# STM32L162xD register map
File version: 1.0
Registers are 32-bit, read-write, reset 0x0 unless marked. A register's access mark holds for its fields unless they carry their own. Offsets are from the block's base; [hi:lo] are bit positions; {n}, {i} and the like mark numbered series; 'fields as' and 'values as' point back to an identical list.

## RCC — Reset and Clock Control
Base 0x40023800
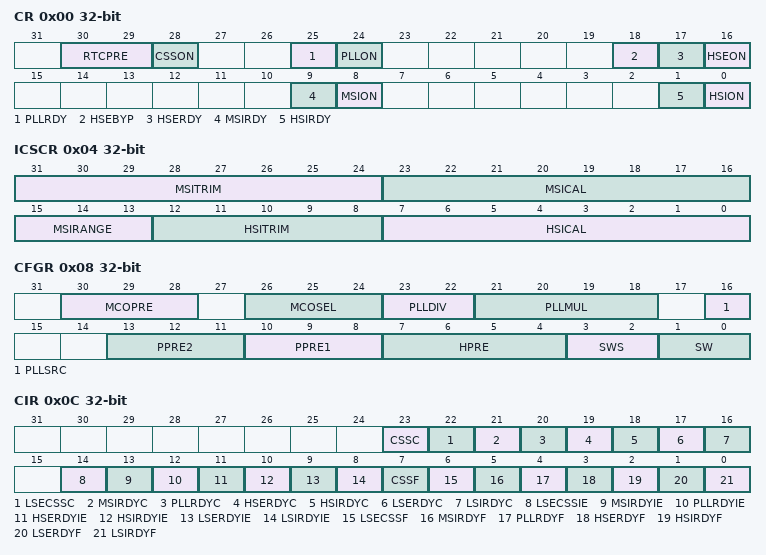
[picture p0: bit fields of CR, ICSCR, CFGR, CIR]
0x00 CR — RCC clock control register
  [30:29] RTCPRE — RTC/LCD Prescaler
    0=DIV_2 (HSE is divided by 2 for RTC clock); 1=DIV_4 (HSE is divided by 4 for RTC clock); 2=DIV_8 (HSE is divided by 8 for RTC clock); 3=DIV_16 (HSE is divided by 16 for RTC clock)
  [28] CSSON — Clock Security System enable
  [25] PLLRDY — PLL clock ready flag
  [24] PLLON — PLL enable
  [18] HSEBYP — External High Speed clock Bypass
  [17] HSERDY — External High Speed clock ready flag
  [16] HSEON — External High Speed clock enable
  [9] MSIRDY — Internal Multi Speed clock ready flag
  [8] MSION — Internal Multi Speed clock enable
  [1] HSIRDY — Internal High Speed clock ready flag
  [0] HSION — Internal High Speed clock enable
0x04 ICSCR — RCC Internal clock sources calibration register
  [31:24] MSITRIM — Internal Multi Speed clock trimming
  [23:16] MSICAL — Internal Multi Speed clock Calibration
  [15:13] MSIRANGE — Internal Multi Speed clock Range
    0=MSI = 65.536 KHz; 1=MSI = 131.072 KHz; 2=MSI = 262.144 KHz; 3=MSI = 524.288 KHz; 4=MSI = 1.048 MHz; 5=MSI = 2.097 MHz; 6=MSI = 4.194 MHz
  [12:8] HSITRIM — Internal High Speed clock trimming
  [7:0] HSICAL — Internal High Speed clock Calibration
0x08 CFGR — RCC Clock configuration register
  [30:28] MCOPRE — MCOPRE[2:0] bits (Microcontroller Clock Output Prescaler)
  [26:24] MCOSEL — MCO[2:0] bits (Microcontroller Clock Output)
  [23:22] PLLDIV — PLLDIV[1:0] bits (PLL Output Division)
    1=DIV_2 (PLL clock output = PLLVCO / 2); 2=DIV_3 (PLL clock output = PLLVCO / 3); 3=DIV_4 (PLL clock output = PLLVCO / 4)
  [21:18] PLLMUL — PLLMUL[3:0] bits (PLL multiplication factor)
    0=MUL_3 (PLL input clock * 3); 1=MUL_4 (PLL input clock * 4); 2=MUL_6 (PLL input clock * 6); 3=MUL_8 (PLL input clock * 8); 4=MUL_12 (PLL input clock * 12); 5=MUL_16 (PLL input clock * 16); 6=MUL_24 (PLL input clock * 24); 7=MUL_32 (PLL input clock * 32); 8=MUL_48 (PLL input clock * 48)
  [16] PLLSRC — PLL entry clock source
    0=HSI (HSI clock selected as PLL entry clock source); 1=HSE (HSE clock selected as PLL entry clock source)
  [13:11] PPRE2 — PRE2[2:0] bits (APB2 prescaler)
    0=DIV_1 (HCLK not divided); 4=DIV_2 (HCLK divided by 2); 5=DIV_4 (HCLK divided by 4); 6=DIV_8 (HCLK divided by 8); 7=DIV_16 (HCLK divided by 16)
  [10:8] PPRE1 — PRE1[2:0] bits (APB1 prescaler)
    values as PPRE2
  [7:4] HPRE — HPRE[3:0] bits (AHB prescaler)
    0=DIV_1 (SYSCLK not divided); 8=DIV_2 (SYSCLK divided by 2); 9=DIV_4 (SYSCLK divided by 4); 10=DIV_8 (SYSCLK divided by 8); 11=DIV_16 (SYSCLK divided by 16); 12=DIV_64 (SYSCLK divided by 64); 13=DIV_128 (SYSCLK divided by 128); 14=DIV_256 (SYSCLK divided by 256); 15=DIV_512 (SYSCLK divided by 512)
  [3:2] SWS — SWS[1:0] bits (System Clock Switch Status)
    0=MSI (MSI used as system clock); 1=HSI (HSI used as system clock); 2=HSE (HSE used as system clock); 3=PLL (PLL used as system clock)
  [1:0] SW — SW[1:0] bits (System clock Switch)
    0=MSI (MSI selection as system clock); 1=HSI (HSI selection as system clock); 2=HSE (HSE selection as system clock); 3=PLL (PLL selection as system clock)
0x0C CIR — RCC Clock interrupt register
  [23] CSSC — Clock Security System Interrupt Clear
  [22] LSECSSC — LSE CSS Interrupt Clear
  [21] MSIRDYC — MSI Ready Interrupt Clear
  [20] PLLRDYC — PLL Ready Interrupt Clear
  [19] HSERDYC — HSE Ready Interrupt Clear
  [18] HSIRDYC — HSI Ready Interrupt Clear
  [17] LSERDYC — LSE Ready Interrupt Clear
  [16] LSIRDYC — LSI Ready Interrupt Clear
  [14] LSECSSIE — LSE CSS Interrupt Enable
  [13] MSIRDYIE — MSI Ready Interrupt Enable
  [12] PLLRDYIE — PLL Ready Interrupt Enable
  [11] HSERDYIE — HSE Ready Interrupt Enable
  [10] HSIRDYIE — HSI Ready Interrupt Enable
  [9] LSERDYIE — LSE Ready Interrupt Enable
  [8] LSIRDYIE — LSI Ready Interrupt Enable
  [7] CSSF — Clock Security System Interrupt flag
  [6] LSECSSF — LSE CSS Interrupt flag
  [5] MSIRDYF — MSI Ready Interrupt flag
  [4] PLLRDYF — PLL Ready Interrupt flag
  [3] HSERDYF — HSE Ready Interrupt flag
  [2] HSIRDYF — HSI Ready Interrupt flag
  [1] LSERDYF — LSE Ready Interrupt flag
  [0] LSIRDYF — LSI Ready Interrupt flag
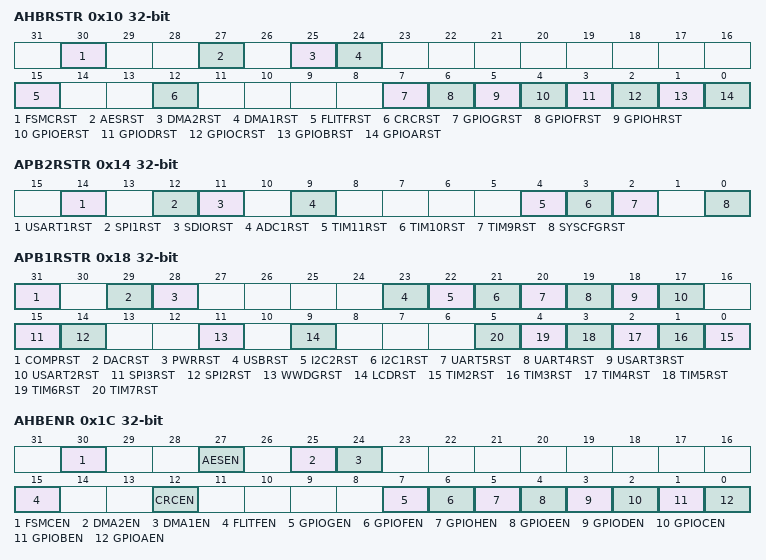
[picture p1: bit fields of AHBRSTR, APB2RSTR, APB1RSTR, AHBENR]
0x10 AHBRSTR — RCC AHB peripheral reset register
  [30] FSMCRST — FSMC reset
  [27] AESRST — AES reset
  [25] DMA2RST — DMA2 reset
  [24] DMA1RST — DMA1 reset
  [15] FLITFRST — FLITF reset
  [12] CRCRST — CRC reset
  [7] GPIOGRST — GPIO port G reset
  [6] GPIOFRST — GPIO port F reset
  [5] GPIOHRST — GPIO port H reset
  [4] GPIOERST — GPIO port E reset
  [3] GPIODRST — GPIO port D reset
  [2] GPIOCRST — GPIO port C reset
  [1] GPIOBRST — GPIO port B reset
  [0] GPIOARST — GPIO port A reset
0x14 APB2RSTR — RCC APB2 peripheral reset register
  [14] USART1RST — USART1 reset
  [12] SPI1RST — SPI1 reset
  [11] SDIORST — SDIO reset
  [9] ADC1RST — ADC1 reset
  [4] TIM11RST — TIM11 reset
  [3] TIM10RST — TIM10 reset
  [2] TIM9RST — TIM9 reset
  [0] SYSCFGRST — System Configuration SYSCFG reset
0x18 APB1RSTR — RCC APB1 peripheral reset register
  [31] COMPRST — Comparator interface reset
  [29] DACRST — DAC interface reset
  [28] PWRRST — Power interface reset
  [23] USBRST — USB reset
  [22] I2C2RST — I2C 2 reset
  [21] I2C1RST — I2C 1 reset
  [20] UART5RST — UART 5 reset
  [19] UART4RST — UART 4 reset
  [18] USART3RST — USART 3 reset
  [17] USART2RST — USART 2 reset
  [15] SPI3RST — SPI 3 reset
  [14] SPI2RST — SPI 2 reset
  [11] WWDGRST — Window Watchdog reset
  [9] LCDRST — LCD reset
  [n-2] TIM{n}RST (n=2..7) — Timer {n} reset
0x1C AHBENR — RCC AHB peripheral clock enable register
  [30] FSMCEN — FSMC clock enable
  [27] AESEN — AES clock enable
  [25] DMA2EN — DMA2 clock enable
  [24] DMA1EN — DMA1 clock enable
  [15] FLITFEN
  [12] CRCEN — CRC clock enable
  [7] GPIOGEN — GPIO port G clock enable
  [6] GPIOFEN — GPIO port F clock enable
  [5] GPIOHEN — GPIO port H clock enable
  [4] GPIOEEN — GPIO port E clock enable
  [3] GPIODEN — GPIO port D clock enable
  [2] GPIOCEN — GPIO port C clock enable
  [1] GPIOBEN — GPIO port B clock enable
  [0] GPIOAEN — GPIO port A clock enable
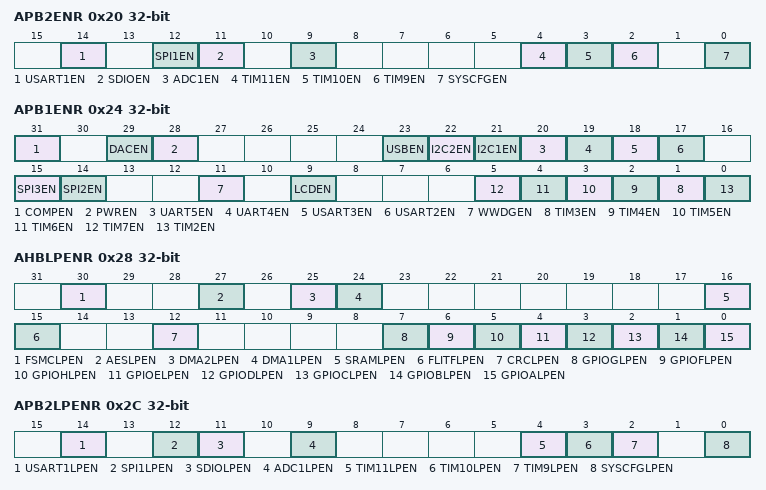
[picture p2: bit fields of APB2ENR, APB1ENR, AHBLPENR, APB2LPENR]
0x20 APB2ENR — RCC APB2 peripheral clock enable register
  [14] USART1EN — USART1 clock enable
  [12] SPI1EN — SPI1 clock enable
  [11] SDIOEN — SDIO clock enable
  [9] ADC1EN — ADC1 clock enable
  [4] TIM11EN — TIM11 Timer clock enable
  [3] TIM10EN — TIM10 interface clock enable
  [2] TIM9EN — TIM9 interface clock enable
  [0] SYSCFGEN — System Configuration SYSCFG clock enable
0x24 APB1ENR — RCC APB1 peripheral clock enable register
  [31] COMPEN — Comparator interface clock enable
  [29] DACEN — DAC interface clock enable
  [28] PWREN — Power interface clock enable
  [23] USBEN — USB clock enable
  [22] I2C2EN — I2C 2 clock enable
  [21] I2C1EN — I2C 1 clock enable
  [20] UART5EN — UART 5 clock enable
  [19] UART4EN — UART 4 clock enable
  [18] USART3EN — USART 3 clock enable
  [17] USART2EN — USART 2 clock enable
  [15] SPI3EN — SPI 3 clock enable
  [14] SPI2EN — SPI 2 clock enable
  [11] WWDGEN — Window Watchdog clock enable
  [9] LCDEN — LCD clock enable
  [n-2] TIM{n}EN (n=3..7) — Timer {n} clock enable
  [0] TIM2EN — Timer 2 clock enabled
0x28 AHBLPENR — RCC AHB peripheral clock enable in low power mode register
  [30] FSMCLPEN — FSMC clock enabled in sleep mode
  [27] AESLPEN — AES clock enabled in sleep mode
  [25] DMA2LPEN — DMA2 clock enabled in sleep mode
  [24] DMA1LPEN — DMA1 clock enabled in sleep mode
  [16] SRAMLPEN — SRAM clock enabled in sleep mode
  [15] FLITFLPEN
  [12] CRCLPEN — CRC clock enabled in sleep mode
  [7] GPIOGLPEN — GPIO port G clock enabled in sleep mode
  [6] GPIOFLPEN — GPIO port F clock enabled in sleep mode
  [5] GPIOHLPEN — GPIO port H clock enabled in sleep mode
  [4] GPIOELPEN — GPIO port E clock enabled in sleep mode
  [3] GPIODLPEN — GPIO port D clock enabled in sleep mode
  [2] GPIOCLPEN — GPIO port C clock enabled in sleep mode
  [1] GPIOBLPEN — GPIO port B clock enabled in sleep mode
  [0] GPIOALPEN — GPIO port A clock enabled in sleep mode
0x2C APB2LPENR — RCC APB2 peripheral clock enable in low power mode register
  [14] USART1LPEN — USART1 clock enabled in sleep mode
  [12] SPI1LPEN — SPI1 clock enabled in sleep mode
  [11] SDIOLPEN — SDIO clock enabled in sleep mode
  [9] ADC1LPEN — ADC1 clock enabled in sleep mode
  [4] TIM11LPEN — TIM11 Timer clock enabled in sleep mode
  [3] TIM10LPEN — TIM10 interface clock enabled in sleep mode
  [2] TIM9LPEN — TIM9 interface clock enabled in sleep mode
  [0] SYSCFGLPEN — System Configuration SYSCFG clock enabled in sleep mode
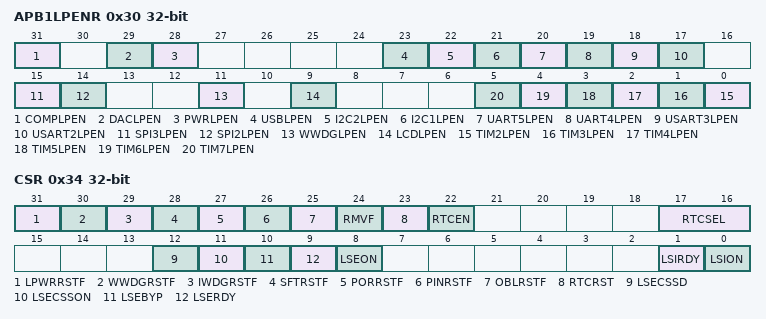
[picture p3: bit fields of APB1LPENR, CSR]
0x30 APB1LPENR — RCC APB1 peripheral clock enable in low power mode register
  [31] COMPLPEN — Comparator interface clock enabled in sleep mode
  [29] DACLPEN — DAC interface clock enabled in sleep mode
  [28] PWRLPEN — Power interface clock enabled in sleep mode
  [23] USBLPEN — USB clock enabled in sleep mode
  [22] I2C2LPEN — I2C 2 clock enabled in sleep mode
  [21] I2C1LPEN — I2C 1 clock enabled in sleep mode
  [20] UART5LPEN — UART 5 clock enabled in sleep mode
  [19] UART4LPEN — UART 4 clock enabled in sleep mode
  [18] USART3LPEN — USART 3 clock enabled in sleep mode
  [17] USART2LPEN — USART 2 clock enabled in sleep mode
  [15] SPI3LPEN — SPI 3 clock enabled in sleep mode
  [14] SPI2LPEN — SPI 2 clock enabled in sleep mode
  [11] WWDGLPEN — Window Watchdog clock enabled in sleep mode
  [9] LCDLPEN — LCD clock enabled in sleep mode
  [n-2] TIM{n}LPEN (n=2..7) — Timer {n} clock enabled in sleep mode
0x34 CSR — RCC Control/status register
  [31] LPWRRSTF — Low-Power reset flag
  [30] WWDGRSTF — Window watchdog reset flag
  [29] IWDGRSTF — Independent Watchdog reset flag
  [28] SFTRSTF — Software Reset flag
  [27] PORRSTF — POR/PDR reset flag
  [26] PINRSTF — PIN reset flag
  [25] OBLRSTF — Option Bytes Loader reset flag
  [24] RMVF — Remove reset flag
  [23] RTCRST — RTC reset
  [22] RTCEN — RTC clock enable
  [17:16] RTCSEL — RTCSEL[1:0] bits (RTC clock source selection)
    0=NONE (No clock used as RTC clock); 1=LSE (LSE oscillator clock used as RTC clock); 2=LSI (LSI oscillator clock used as RTC clock); 3=HSE
  [12] LSECSSD — External Low Speed oscillator CSS Detected
  [11] LSECSSON — External Low Speed oscillator CSS Enable
  [10] LSEBYP — External Low Speed oscillator Bypass
  [9] LSERDY — External Low Speed oscillator Ready
  [8] LSEON — External Low Speed oscillator enable
  [1] LSIRDY — Internal Low Speed oscillator Ready
  [0] LSION — Internal Low Speed oscillator enable
